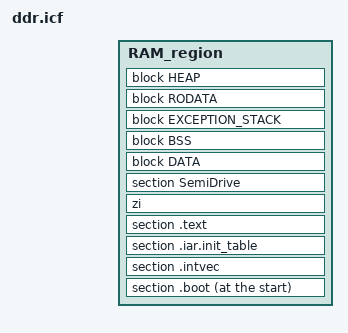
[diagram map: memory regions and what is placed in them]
define memory mem with size = 4G;
define region RAM_region =
    mem:[from MEMBASE to MEMBASE + MEMSIZE - 1];

define block _DATA with alignment = 4 { section .data };
define block BSS with alignment = 4 { section .bss };
define block EXCEPTION_STACK with alignment = 4 { section .except.stack };
define block FAULT_TABLE { section .rodata.fault_handler_table };
define block COMMANDS { section .commands };
define block RODATA with alignment = 4 {
    block FAULT_TABLE,
    section .rodata
};
define block DATA {
    block _DATA,
    block COMMANDS
};
define block HEAP with alignment = 4, maximum size = 0x20000,
    expanding size { section .heap };

do not initialize { section .except.stack };

place at start of RAM_region { section .boot };
place in RAM_region { section .intvec };
place in RAM_region { section .iar.init_table };
place in RAM_region { section .text };
place in RAM_region { zi };
place in RAM_region { section SemiDrive };
place in RAM_region { block DATA };
place in RAM_region { block BSS };
place in RAM_region { block EXCEPTION_STACK };
place in RAM_region { block RODATA };
place in RAM_region { block HEAP };
